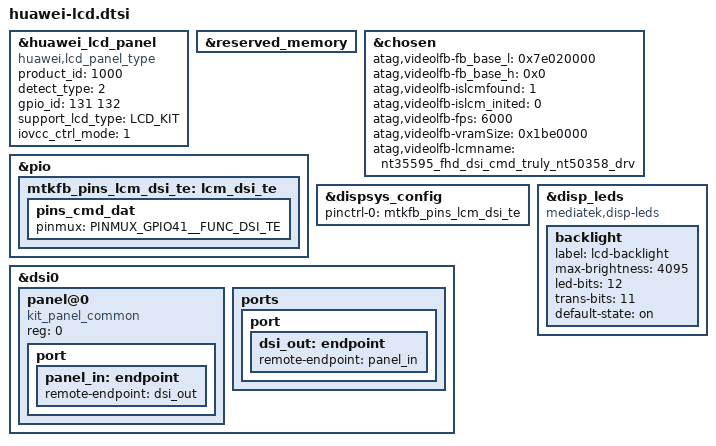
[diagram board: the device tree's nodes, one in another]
#include "../lcdkit3.0/ang/devkit_lcd_kit.dtsi"

&huawei_lcd_panel {
		compatible = "huawei,lcd_panel_type";
		product_id = <1000>;
		detect_type = <2>; /*0:DETECT_GPIOID  1:DETECT_CHIPID  2:DETECT_LCD_TYPE */
		gpio_id = <131 132>; /*ID0 ID1*/
		support_lcd_type = "LCD_KIT";
		iovcc_ctrl_mode = <1>;
};

&reserved_memory {
};


/* chosen */
&chosen {

	atag,videolfb-fb_base_l = <0x7e020000>;
	atag,videolfb-fb_base_h = <0x0>;
	atag,videolfb-islcmfound = <1>;
	atag,videolfb-islcm_inited = <0>;
	atag,videolfb-fps= <6000>;
	atag,videolfb-vramSize= <0x1be0000>;
	atag,videolfb-lcmname=
		"nt35595_fhd_dsi_cmd_truly_nt50358_drv";
};

/* DISPSYS GPIO standardization */
&pio {
	mtkfb_pins_lcm_dsi_te: lcm_dsi_te {
		pins_cmd_dat {
			pinmux = <PINMUX_GPIO41__FUNC_DSI_TE>;
		};
	};
};

&dispsys_config {
	pinctrl-names =
		"mode_te_te";
	pinctrl-0 = <&mtkfb_pins_lcm_dsi_te>;
	status = "okay";
};

&dsi0 {
	status = "okay";
	#address-cells = <1>;
	#size-cells = <0>;
	panel@0 {
		compatible = "kit_panel_common";
		reg = <0>;
		port {
			panel_in: endpoint {
				remote-endpoint = <&dsi_out>;
			};
		};
	};
	ports {
		port {
			dsi_out: endpoint {
				remote-endpoint = <&panel_in>;
			};
		};
	};
};

&disp_leds {
	compatible = "mediatek,disp-leds";

	backlight {
		label = "lcd-backlight";
		max-brightness = <4095>;
		led-bits = <12>;
		trans-bits = <11>;
		default-state = "on";
	};
};
